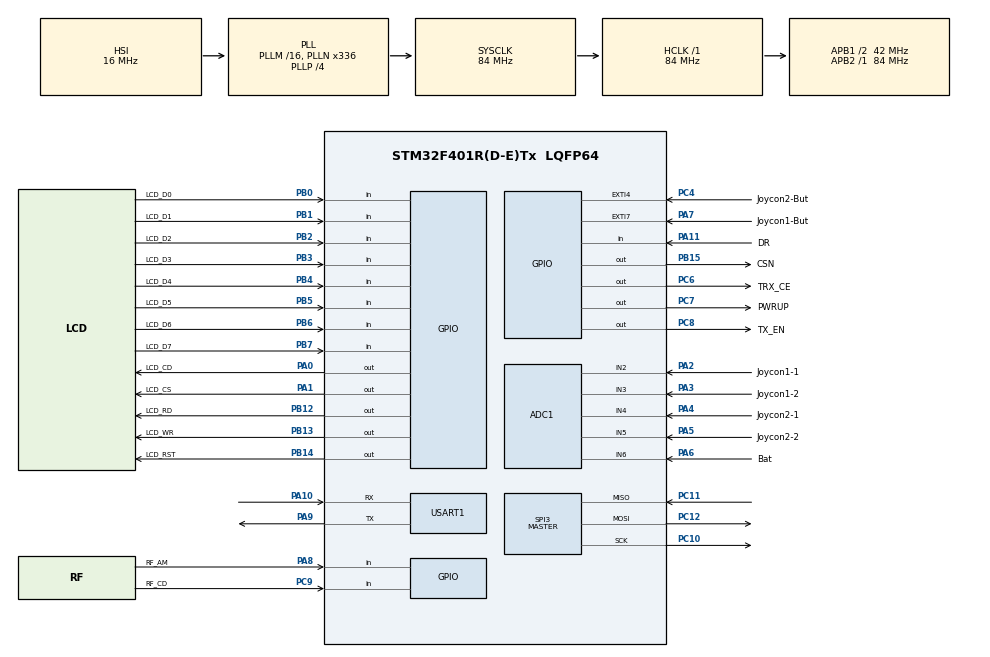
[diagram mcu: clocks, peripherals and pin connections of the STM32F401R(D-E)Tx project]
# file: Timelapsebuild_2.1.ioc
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ADC1.Channel-0\#ChannelRegularConversion=ADC_CHANNEL_3
ADC1.NbrOfConversionFlag=1
ADC1.Rank-0\#ChannelRegularConversion=1
ADC1.SamplingTime-0\#ChannelRegularConversion=ADC_SAMPLETIME_3CYCLES
ADC1.master=1
Mcu.Family=STM32F4
Mcu.Name=STM32F401R(D-E)Tx
Mcu.Package=LQFP64
NVIC.EXTI4_IRQn=true\:0\:0\:false\:false\:true\:true
NVIC.EXTI9_5_IRQn=true\:0\:0\:false\:false\:true\:true
NVIC.PriorityGroup=NVIC_PRIORITYGROUP_4
PA0-WKUP.GPIO_Label=LCD_CD
PA0-WKUP.GPIO_PuPd=GPIO_PULLUP
PA0-WKUP.Signal=GPIO_Output
PA1.GPIO_Label=LCD_CS
PA1.GPIO_PuPd=GPIO_PULLUP
PA1.Signal=GPIO_Output
PA10.Mode=Asynchronous
PA10.Signal=USART1_RX
PA11.GPIO_Label=DR
PA11.Signal=GPIO_Input
PA13.Mode=Serial_Wire
PA13.Signal=SYS_JTMS-SWDIO
PA14.Mode=Serial_Wire
PA14.Signal=SYS_JTCK-SWCLK
PA2.GPIO_Label=Joycon1-1
PA2.Signal=ADCx_IN2
PA3.GPIO_Label=Joycon1-2
PA3.Signal=ADCx_IN3
PA4.GPIO_Label=Joycon2-1
PA4.Signal=ADCx_IN4
PA5.GPIO_Label=Joycon2-2
PA5.Signal=ADCx_IN5
PA6.GPIO_Label=Bat
PA6.Signal=ADCx_IN6
PA7.GPIO_Label=Joycon1-But
PA7.GPIO_ModeDefaultEXTI=GPIO_MODE_IT_FALLING
PA7.GPIO_PuPd=GPIO_PULLUP
PA7.Signal=GPXTI7
PA8.GPIO_Label=RF_AM
PA8.Signal=GPIO_Input
PA9.Mode=Asynchronous
PA9.Signal=USART1_TX
PB0.GPIO_Label=LCD_D0
PB0.Signal=GPIO_Input
PB1.GPIO_Label=LCD_D1
PB1.Signal=GPIO_Input
PB12.GPIO_Label=LCD_RD
PB12.GPIO_PuPd=GPIO_PULLUP
PB12.Signal=GPIO_Output
PB13.GPIO_Label=LCD_WR
PB13.GPIO_PuPd=GPIO_PULLUP
PB13.Signal=GPIO_Output
PB14.GPIO_Label=LCD_RST
PB14.GPIO_PuPd=GPIO_PULLUP
PB14.Signal=GPIO_Output
PB15.GPIO_Label=CSN
PB15.PinState=GPIO_PIN_SET
PB15.Signal=GPIO_Output
PB2.GPIO_Label=LCD_D2
PB2.Signal=GPIO_Input
PB3.GPIO_Label=LCD_D3
PB3.Signal=GPIO_Input
PB4.GPIO_Label=LCD_D4
PB4.Signal=GPIO_Input
PB5.GPIO_Label=LCD_D5
PB5.Signal=GPIO_Input
PB6.GPIO_Label=LCD_D6
PB6.Signal=GPIO_Input
PB7.GPIO_Label=LCD_D7
PB7.Signal=GPIO_Input
PC10.Mode=Full_Duplex_Master
PC10.Signal=SPI3_SCK
PC11.Mode=Full_Duplex_Master
PC11.Signal=SPI3_MISO
PC12.Mode=Full_Duplex_Master
PC12.Signal=SPI3_MOSI
PC4.GPIO_Label=Joycon2-But
PC4.GPIO_ModeDefaultEXTI=GPIO_MODE_IT_FALLING
PC4.GPIO_PuPd=GPIO_PULLUP
PC4.Signal=GPXTI4
PC6.GPIO_Label=TRX_CE
PC6.Signal=GPIO_Output
PC7.GPIO_Label=PWRUP
PC7.Signal=GPIO_Output
PC8.GPIO_Label=TX_EN
PC8.Signal=GPIO_Output
PC9.GPIO_Label=RF_CD
PC9.Signal=GPIO_Input
ProjectManager.HeapSize=0x200
ProjectManager.StackSize=0x400
ProjectManager.TargetToolchain=SW4STM32
RCC.48MHZClocksFreq_Value=84000000
RCC.AHBFreq_Value=84000000
RCC.APB1CLKDivider=RCC_HCLK_DIV2
RCC.APB1Freq_Value=42000000
RCC.APB1TimFreq_Value=84000000
RCC.APB2Freq_Value=84000000
RCC.APB2TimFreq_Value=84000000
RCC.CortexFreq_Value=84000000
RCC.HCLKFreq_Value=84000000
RCC.HSE_VALUE=25000000
RCC.HSI_VALUE=16000000
RCC.LSE_VALUE=32768
RCC.PLLN=336
RCC.PLLP=RCC_PLLP_DIV4
RCC.SYSCLKFreq_VALUE=84000000
RCC.SYSCLKSource=RCC_SYSCLKSOURCE_PLLCLK
RCC.VCOOutputFreq_Value=336000000
SH.ADCx_IN2.0=ADC1_IN2,IN2
SH.ADCx_IN3.0=ADC1_IN3,IN3
SH.ADCx_IN4.0=ADC1_IN4,IN4
SH.ADCx_IN5.0=ADC1_IN5,IN5
SH.ADCx_IN6.0=ADC1_IN6,IN6
SPI3.BaudRatePrescaler=SPI_BAUDRATEPRESCALER_8
SPI3.Direction=SPI_DIRECTION_2LINES
SPI3.Mode=SPI_MODE_MASTER
SPI3.VirtualType=VM_MASTER
USART1.VirtualMode=VM_ASYNC
board=custom

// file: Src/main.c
/* USER CODE BEGIN Header */
/**
  ******************************************************************************
  * @file           : main.c
  * @brief          : Main program body
  ******************************************************************************
  ** This notice applies to any and all portions of this file
  * that are not between comment pairs USER CODE BEGIN and
  * USER CODE END. Other portions of this file, whether
  * inserted by the user or by software development tools
  * are owned by their respective copyright owners.
  *
  * COPYRIGHT(c) 2019 STMicroelectronics
  *
  * Redistribution and use in source and binary forms, with or without modification,
  * are permitted provided that the following conditions are met:
  *   1. Redistributions of source code must retain the above copyright notice,
  *      this list of conditions and the following disclaimer.
  *   2. Redistributions in binary form must reproduce the above copyright notice,
  *      this list of conditions and the following disclaimer in the documentation
  *      and/or other materials provided with the distribution.
  *   3. Neither the name of STMicroelectronics nor the names of its contributors
  *      may be used to endorse or promote products derived from this software
  *      without specific prior written permission.
  *
  * THIS SOFTWARE IS PROVIDED BY THE COPYRIGHT HOLDERS AND CONTRIBUTORS "AS IS"
  * AND ANY EXPRESS OR IMPLIED WARRANTIES, INCLUDING, BUT NOT LIMITED TO, THE
  * IMPLIED WARRANTIES OF MERCHANTABILITY AND FITNESS FOR A PARTICULAR PURPOSE ARE
  * DISCLAIMED. IN NO EVENT SHALL THE COPYRIGHT HOLDER OR CONTRIBUTORS BE LIABLE
  * FOR ANY DIRECT, INDIRECT, INCIDENTAL, SPECIAL, EXEMPLARY, OR CONSEQUENTIAL
  * DAMAGES (INCLUDING, BUT NOT LIMITED TO, PROCUREMENT OF SUBSTITUTE GOODS OR
  * SERVICES; LOSS OF USE, DATA, OR PROFITS; OR BUSINESS INTERRUPTION) HOWEVER
  * CAUSED AND ON ANY THEORY OF LIABILITY, WHETHER IN CONTRACT, STRICT LIABILITY,
  * OR TORT (INCLUDING NEGLIGENCE OR OTHERWISE) ARISING IN ANY WAY OUT OF THE USE
  * OF THIS SOFTWARE, EVEN IF ADVISED OF THE POSSIBILITY OF SUCH DAMAGE.
  *
  ******************************************************************************
  */
/* USER CODE END Header */

#include "main.h"
#include "adc.h"
#include "spi.h"
#include "usart.h"
#include "gpio.h"

/* USER CODE BEGIN Includes */
#include "App.h"
#include "LCDWIKI.h"
/* USER CODE END Includes */

void SystemClock_Config(void);

int main(void)
{

  /* MCU Configuration--------------------------------------------------------*/

  /* Reset of all peripherals, Initializes the Flash interface and the Systick. */
  HAL_Init();

  /* Configure the system clock */
  SystemClock_Config();

  /* Initialize all configured peripherals */
  MX_GPIO_Init();
  MX_USART1_UART_Init();
  MX_SPI3_Init();
  MX_ADC1_Init();
  /* USER CODE BEGIN 2 */
  tft_delay = &HAL_Delay;
  App_Start();
  /* USER CODE END 2 */

  /* Infinite loop */
  while (1)
  {

  }
}

void SystemClock_Config(void)
{
  RCC_OscInitTypeDef RCC_OscInitStruct = {0};
  RCC_ClkInitTypeDef RCC_ClkInitStruct = {0};

  /**Configure the main internal regulator output voltage
  */
  __HAL_RCC_PWR_CLK_ENABLE();
  __HAL_PWR_VOLTAGESCALING_CONFIG(PWR_REGULATOR_VOLTAGE_SCALE2);
  /**Initializes the CPU, AHB and APB busses clocks
  */
  RCC_OscInitStruct.OscillatorType = RCC_OSCILLATORTYPE_HSI;
  RCC_OscInitStruct.HSIState = RCC_HSI_ON;
  RCC_OscInitStruct.HSICalibrationValue = RCC_HSICALIBRATION_DEFAULT;
  RCC_OscInitStruct.PLL.PLLState = RCC_PLL_ON;
  RCC_OscInitStruct.PLL.PLLSource = RCC_PLLSOURCE_HSI;
  RCC_OscInitStruct.PLL.PLLM = 16;
  RCC_OscInitStruct.PLL.PLLN = 336;
  RCC_OscInitStruct.PLL.PLLP = RCC_PLLP_DIV4;
  RCC_OscInitStruct.PLL.PLLQ = 4;
  if (HAL_RCC_OscConfig(&RCC_OscInitStruct) != HAL_OK)
  {
    Error_Handler();
  }
  /**Initializes the CPU, AHB and APB busses clocks
  */
  RCC_ClkInitStruct.ClockType = RCC_CLOCKTYPE_HCLK|RCC_CLOCKTYPE_SYSCLK
                              |RCC_CLOCKTYPE_PCLK1|RCC_CLOCKTYPE_PCLK2;
  RCC_ClkInitStruct.SYSCLKSource = RCC_SYSCLKSOURCE_PLLCLK;
  RCC_ClkInitStruct.AHBCLKDivider = RCC_SYSCLK_DIV1;
  RCC_ClkInitStruct.APB1CLKDivider = RCC_HCLK_DIV2;
  RCC_ClkInitStruct.APB2CLKDivider = RCC_HCLK_DIV1;

  if (HAL_RCC_ClockConfig(&RCC_ClkInitStruct, FLASH_LATENCY_2) != HAL_OK)
  {
    Error_Handler();
  }
}

void Error_Handler(void)
{
}

/************************ (C) COPYRIGHT STMicroelectronics *****END OF FILE****/
